# STM32WBA50 register map
File version: 1.0
CPU: CM33 r0p1, little endian, MPU, FPU, 4 interrupt priority bits
Registers are 32-bit, read-write, reset 0x0 unless marked. A register's access mark holds for its fields unless they carry their own. Offsets are from the block's base; lines under a group give offsets from that group; [hi:lo] are bit positions; {n}, {i} and the like mark numbered series; 'fields as' and 'values as' point back to an identical list; <NAME> marks a mode.

## Memory map
0x40000000 TIM2 size 0x3E4 — TIM2 address block description
0x40002C00 WWDG size 0x400 — System window watchdog
0x40003000 IWDG size 0x400 — Independent watchdog
0x40012C00 TIM1 size 0x3E4 — TIM1 address block description
0x40013800 USART1 size 0x400 — USART register block
0x40014400 TIM16 size 0x3E4 — TIM16 address block description
0x40020000 GPDMA size 0x1000 — General purpose direct memory access controller
0x40022000 FLASH size 0x400 — Embedded Flash memory
0x40023000 CRC size 0x18 — CRC register block
0x40024000 TSC size 0x400 — Touch sensing controller
0x40026000 RAMCFG size 0x1000 — RAMs configuration controller
0x40030400 ICACHE size 0x400 — Instruction cache
0x42020000 GPIOA size 0x400 — General-purpose I/Os
0x42020400 GPIOB size 0x400 — General-purpose I/Os
0x42020800 GPIOC size 0x400 — General-purpose I/Os
0x42021C00 GPIOH size 0x400 — General-purpose I/Os
0x420C0000 AES size 0x400 — Advanced encryption standard hardware accelerator
0x420C0400 HASH size 0x400 — HASH register block
0x420C0800 RNG size 0x400 — RNG register block
0x420C1C00 HSEM size 0x400 — Hardware semaphore
0x420C2000 PKA size 0x2000 — Private key accelerator
0x46000400 SYSCFG size 0x400 — System configuration controller
0x46002000 SPI3 size 0x400 — Serial peripheral interface
0x46002400 LPUART1 size 0x34 — LPUART address block description
0x46002800 I2C3 size 0x400 — Inter-integrated circuit
0x46004400 LPTIM1 size 0x400 — Low power timer
0x46007800 RTC size 0x400 — Real-time clock
0x46007C00 TAMP size 0x400 — Tamper and backup registers
0x46020800 PWR size 0x400 — Power control
0x46020C00 RCC size 0x400 — Reset and clock control
0x46021000 ADC4 size 0x400 — ADC register block
0x46022000 EXTI size 0x400 — External interrupt/event controller
0xE0044000 DBGMCU size 0x1000 — DBGMCU address block description

## Interrupts
0 WWDG — Window Watchdog interrupt
1 PDV (EXTI) — Power voltage monitor
2 RTC — RTC non-secure global interrupts
3 RTC_S (RTC) — RTC secure global interrupts
4 TAMP — Tamper global interrupts
5 RAMCFG — RAM configuration global interrupt
6 FLASH — Flash interface non-secure global interrupt,Flash ECC single error correction interrupt
9 RCC — RCC non-secure global interrupt
10 RCC_S (RCC) — RCC Ssecure global interrupt
{n+11} EXTI{n} (EXTI) (n=0..15) — EXTI line{n} interrupt
{n+29} GPDMA1_CH{n} (GPDMA) (n=0..7) — GPDMA1 channel {n} global interrupt
37 TIM1_BRK_TERR_IERR (TIM1) — TIM1 Break - transition error -index error
38 TIM1_UP (TIM1) — TIM1 Update
39 TIM1_TRG_COM_DIR_IDX (TIM1) — TIM1 Trigger and Commutation - direction change interrupt -index
40 TIM1_CC (TIM1) — TIM1 Capture Compare interrupt
41 TIM2 — TIM2 global interrupt
46 USART1 — USART1 global interrupt
48 LPUART1 — LPUART1 global interrupt
49 LPTIM1 — LPTIM1 global interrupt
51 TIM16 — TIM16 global interrupt
54 I2C3_EV (I2C3) — I2C3 event interrupt
55 I2C3_ER (I2C3) — I2C3 error interrupt
57 TSC — TSC global interrupt
58 AES — AES global interrupt
59 RNG — RNG global interrupt
61 HASH — HASH interrupt
62 PKA — PKA global interrupt
63 SPI3 — SPI3 global interrupt
64 ICACHE — Instruction cache global interrupt
65 ADC4 — ADC4 global interrupt
67 WKUP (PWR) — PWR global WKUP pin interrupt
68 HSEM — HSEM non-secure interrupt
69 HSEM_S (HSEM) — HSEM secure interrupt

## CRC — CRC register block
Base 0x40023000
0x00 DR reset 0xFFFFFFFF — CRC data register
  [31:0] DR — Data register bits This register is used to write new data to the CRC calculator. It holds the previous CRC calculation result when it is read. If the data size is less than 32 bits, the least significant bits are used to write/read the correct value.
0x00 DR8 8-bit reset 0xFF (alternate view of DR) — Data register - byte sized
  [7:0] DR8 — Data register bits
0x00 DR16 16-bit reset 0xFFFF (alternate view of DR) — Data register - half-word sized
  [15:0] DR16 — Data register bits
0x04 IDR — CRC independent data register
  [31:0] IDR — General-purpose 32-bit data register bits These bits can be used as a temporary storage location for four bytes. This register is not affected by CRC resets generated by the RESET bit in the CRC_CR register
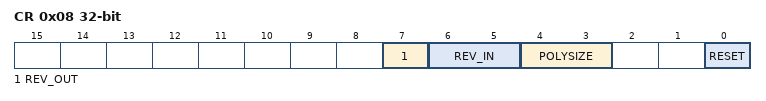
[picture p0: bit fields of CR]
0x08 CR — CRC control register
  [7] REV_OUT — Reverse output data This bit controls the reversal of the bit order of the output data.
    0=Normal (Bit order not affected); 1=Reversed (Bit reversed output)
  [6:5] REV_IN — Reverse input data These bits control the reversal of the bit order of the input data
    0=Normal (Bit order not affected); 1=Byte (Bit reversal done by byte); 2=HalfWord (Bit reversal done by half-word); 3=Word (Bit reversal done by word)
  [4:3] POLYSIZE — Polynomial size These bits control the size of the polynomial.
    0=32-bit polynomial; 1=16-bit polynomial; 2=8-bit polynomial; 3=7-bit polynomial
  [0] RESET — RESET bit This bit is set by software to reset the CRC calculation unit and set the data register to the value stored in the CRC_INIT register. This bit can only be set, it is automatically cleared by hardware
    on write: 1=Resets the CRC calculation unit and sets the data register to 0xFFFF FFFF
0x10 INIT reset 0xFFFFFFFF — CRC initial value
  [31:0] INIT — Programmable initial CRC value This register is used to write the CRC initial value.
0x14 POL reset 0x4C11DB7 — CRC polynomial
  [31:0] POL — Programmable polynomial This register is used to write the coefficients of the polynomial to be used for CRC calculation. If the polynomial size is less than 32 bits, the least significant bits have to be used to program the correct value.
